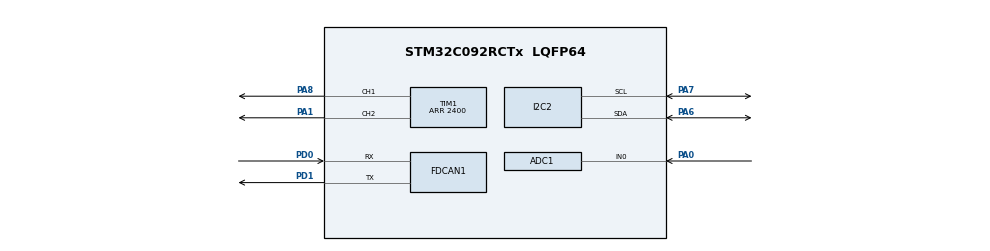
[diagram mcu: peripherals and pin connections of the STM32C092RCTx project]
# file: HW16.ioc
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ADC1.NbrOfConversionFlag=0
ADC1.SelectedChannel=ADC_CHANNEL_0
ADC1.master=1
FDCAN1.AutoRetransmission=ENABLE
FDCAN1.CalculateBaudRateData=1000000
FDCAN1.CalculateBaudRateNominal=1000000
FDCAN1.CalculateTimeBitNominal=1000
FDCAN1.CalculateTimeQuantumNominal=20.833333333333332
FDCAN1.DataSyncJumpWidth=6
FDCAN1.DataTimeSeg1=17
FDCAN1.DataTimeSeg2=6
FDCAN1.FrameFormat=FDCAN_FRAME_FD_BRS
FDCAN1.NominalPrescaler=1
FDCAN1.NominalSyncJumpWidth=12
FDCAN1.NominalTimeSeg1=35
FDCAN1.NominalTimeSeg2=12
FDCAN1.StdFiltersNbr=1
FDCAN1.TransmitPause=ENABLE
I2C2.Timing=0x10805D88
Mcu.Family=STM32C0
Mcu.Name=STM32C092RCTx
Mcu.Package=LQFP64
NUCLEO-C092RC.LD1=true
NUCLEO-C092RC.LD2=true
NUCLEO-C092RC.VCP=true
NVIC.TIM2_IRQn=true\:0\:0\:false\:false\:true\:true\:true\:true
PA0.Mode=IN0
PA0.Signal=ADC1_IN0
PA1.Signal=S_TIM1_CH2
PA6.Mode=I2C
PA6.Signal=I2C2_SDA
PA7.Mode=I2C
PA7.Signal=I2C2_SCL
PA8.Signal=S_TIM1_CH1
PD0.Mode=FDCAN_Activate
PD0.Signal=FDCAN1_RX
PD1.Mode=FDCAN_Activate
PD1.Signal=FDCAN1_TX
ProjectManager.HeapSize=0x200
ProjectManager.StackSize=0x400
ProjectManager.TargetToolchain=STM32CubeIDE
RCC.ADCFreq_Value=48000000
RCC.AHBFreq_Value=48000000
RCC.CortexFreq_Value=48000000
RCC.EXTERNAL_CLOCK_VALUE=12288000
RCC.HCLKFreq_Value=48000000
RCC.HSE_VALUE=8000000
RCC.HSISYSCLKDivider=RCC_HSI_DIV1
RCC.HSI_VALUE=48000000
RCC.LSE_VALUE=32768
RCC.SYSCLKFreq_VALUE=48000000
SH.S_TIM1_CH1.0=TIM1_CH1,PWM Generation1 CH1
SH.S_TIM1_CH2.0=TIM1_CH2,PWM Generation2 CH2
TIM1.Channel-PWM\ Generation1\ CH1=TIM_CHANNEL_1
TIM1.Channel-PWM\ Generation2\ CH2=TIM_CHANNEL_2
TIM1.Period=2400
TIM2.Period=48000
VP_NUCLEO-C092RC_VS_BSP_COMMON.Mode=COMMON
VP_TIM2_VS_ClockSourceINT.Mode=Internal
board=NUCLEO-C092RC

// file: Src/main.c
/* USER CODE BEGIN Header */
/**
  ******************************************************************************
  * @file           : main.c
  * @brief          : Main program body
  ******************************************************************************
  * @attention
  *
  * Copyright (c) 2026 STMicroelectronics.
  * All rights reserved.
  *
  * This software is licensed under terms that can be found in the LICENSE file
  * in the root directory of this software component.
  * If no LICENSE file comes with this software, it is provided AS-IS.
  *
  ******************************************************************************
  */
/* USER CODE END Header */
#include "main.h"

COM_InitTypeDef BspCOMInit;
ADC_HandleTypeDef hadc1;

FDCAN_HandleTypeDef hfdcan1;

I2C_HandleTypeDef hi2c2;

TIM_HandleTypeDef htim1;
TIM_HandleTypeDef htim2;

void SystemClock_Config(void);
static void MX_GPIO_Init(void);
static void MX_FDCAN1_Init(void);
static void MX_ADC1_Init(void);
static void MX_I2C2_Init(void);
static void MX_TIM1_Init(void);
static void MX_TIM2_Init(void);

uint32_t read_adc(void) {
    uint32_t raw;
    HAL_ADC_Start(&hadc1);
    if (HAL_ADC_PollForConversion(&hadc1, 10) == HAL_OK) {
        raw = HAL_ADC_GetValue(&hadc1);
    } else {
        raw = 0;
    }
    HAL_ADC_Stop(&hadc1);
    return raw;
}

#define INA219_ADDR 0x40
#define INA219_REG_CURRENT 0x04
#define INA219_REG_CALIB 0x05
#define INA219_REG_CONFIG 0x00

void writeINA219(int reg, int value) {
    uint8_t buf[3];
    buf[0] = reg;
    buf[1] = value >> 8;
    buf[2] = value & 0xff;
    HAL_I2C_Master_Transmit(&hi2c2, INA219_ADDR<<1, buf, 3, 10);
}

signed short readINA219(unsigned char reg) {
    HAL_I2C_Master_Transmit(&hi2c2, INA219_ADDR<<1, &reg, 1, 10);
    uint8_t buffer[2];
    HAL_I2C_Master_Receive(&hi2c2, INA219_ADDR<<1, buffer, 2, 10);
    return (signed short)((buffer[0]<<8)|buffer[1]);
}

void init_ina219(void) {
    writeINA219(INA219_REG_CALIB, 1024);
    writeINA219(INA219_REG_CONFIG, 0b0011000010001111);
}

// --- PI current control ---
volatile int state = 0;
volatile int counter = 0;
volatile float desired_current = 100.0;   // mA target, sign flips
volatile float integral = 0.0;

#define NSAMP 400
volatile int idx = 0;
float saved_desired[NSAMP];
float saved_actual[NSAMP];

float kp = 2.0;     // TUNE
float ki = 0.15;    // TUNE

void HAL_TIM_PeriodElapsedCallback(TIM_HandleTypeDef *htim) {
    if (htim == &htim2) {
        uint32_t pos = read_adc();

        // safety end-stops
        if (pos < 250 || pos > (4095 - 250)) {
            __HAL_TIM_SET_COMPARE(&htim1, TIM_CHANNEL_1, 2400);
            __HAL_TIM_SET_COMPARE(&htim1, TIM_CHANNEL_2, 2400);
            return;
        }

        if (state == 1) {
            float actual = readINA219(INA219_REG_CURRENT) / 3.0;  // mA
            float error = desired_current - actual;
            integral += error;

            float u = kp * error + ki * integral;
            if (u > 2400) u = 2400;
            if (u < -2400) u = -2400;

            if (u >= 0) {
                __HAL_TIM_SET_COMPARE(&htim1, TIM_CHANNEL_1, 2400);
                __HAL_TIM_SET_COMPARE(&htim1, TIM_CHANNEL_2, 2400 - (int)u);
            } else {
                __HAL_TIM_SET_COMPARE(&htim1, TIM_CHANNEL_2, 2400);
                __HAL_TIM_SET_COMPARE(&htim1, TIM_CHANNEL_1, 2400 - (int)(-u));
            }

            if (idx < NSAMP) {
                saved_desired[idx] = desired_current;
                saved_actual[idx] = actual;
                idx++;
            }

            counter++;
            if (counter >= 100) {
                desired_current = -desired_current;
                counter = 0;
            }
            if (idx >= NSAMP) {
                __HAL_TIM_SET_COMPARE(&htim1, TIM_CHANNEL_1, 2400);
                __HAL_TIM_SET_COMPARE(&htim1, TIM_CHANNEL_2, 2400);
                state = 0;
                counter = 0;
                integral = 0;
            }
        }
    }
}
/* USER CODE END 0 */

int main(void)
{

  /* MCU Configuration--------------------------------------------------------*/

  /* Reset of all peripherals, Initializes the Flash interface and the Systick. */
  HAL_Init();

  /* Configure the system clock */
  SystemClock_Config();

  /* Initialize all configured peripherals */
  MX_GPIO_Init();
  MX_FDCAN1_Init();
  MX_ADC1_Init();
  MX_I2C2_Init();
  MX_TIM1_Init();
  MX_TIM2_Init();
  /* USER CODE BEGIN 2 */
  init_ina219();
  HAL_TIM_Base_Start_IT(&htim2);
  init_ina219();
    HAL_TIM_Base_Start_IT(&htim2);
    __HAL_TIM_SET_COMPARE(&htim1, TIM_CHANNEL_1, 2400);   // 2400 = off
    __HAL_TIM_SET_COMPARE(&htim1, TIM_CHANNEL_2, 2400);   // 2400 = off
    HAL_TIM_PWM_Start(&htim1, TIM_CHANNEL_1);
    HAL_TIM_PWM_Start(&htim1, TIM_CHANNEL_2);
  /* USER CODE END 2 */

  /* Initialize leds */
  BSP_LED_Init(LED_GREEN);
  BSP_LED_Init(LED_BLUE);

  /* Initialize COM1 port (115200, 8 bits (7-bit data + 1 stop bit), no parity */
  BspCOMInit.BaudRate   = 115200;
  BspCOMInit.WordLength = COM_WORDLENGTH_8B;
  BspCOMInit.StopBits   = COM_STOPBITS_1;
  BspCOMInit.Parity     = COM_PARITY_NONE;
  BspCOMInit.HwFlowCtl  = COM_HWCONTROL_NONE;
  if (BSP_COM_Init(COM1, &BspCOMInit) != BSP_ERROR_NONE)
  {
    Error_Handler();
  }

  /* Infinite loop */
  while (1)
  {
	  uint8_t c;
	      if (HAL_UART_Receive(&hcom_uart[COM1], &c, 1, 10) == HAL_OK) {
	          if (c == 'a') {
	              idx = 0;
	              integral = 0;
	              counter = 0;
	              state = 1;
	              while (state == 1) {}

	              // primt data
	              for (int i = 0; i < NSAMP; i++) {
	                  printf("%d,%d,%d\r\n", i, (int)saved_desired[i], (int)saved_actual[i]);
	              }
	          }
	      }
  }
}

void SystemClock_Config(void)
{
  RCC_OscInitTypeDef RCC_OscInitStruct = {0};
  RCC_ClkInitTypeDef RCC_ClkInitStruct = {0};

  __HAL_FLASH_SET_LATENCY(FLASH_LATENCY_1);

  /** Initializes the RCC Oscillators according to the specified parameters
  * in the RCC_OscInitTypeDef structure.
  */
  RCC_OscInitStruct.OscillatorType = RCC_OSCILLATORTYPE_HSI;
  RCC_OscInitStruct.HSIState = RCC_HSI_ON;
  RCC_OscInitStruct.HSIDiv = RCC_HSI_DIV1;
  RCC_OscInitStruct.HSICalibrationValue = RCC_HSICALIBRATION_DEFAULT;
  if (HAL_RCC_OscConfig(&RCC_OscInitStruct) != HAL_OK)
  {
    Error_Handler();
  }

  /** Initializes the CPU, AHB and APB buses clocks
  */
  RCC_ClkInitStruct.ClockType = RCC_CLOCKTYPE_HCLK|RCC_CLOCKTYPE_SYSCLK
                              |RCC_CLOCKTYPE_PCLK1;
  RCC_ClkInitStruct.SYSCLKSource = RCC_SYSCLKSOURCE_HSI;
  RCC_ClkInitStruct.SYSCLKDivider = RCC_SYSCLK_DIV1;
  RCC_ClkInitStruct.AHBCLKDivider = RCC_HCLK_DIV1;
  RCC_ClkInitStruct.APB1CLKDivider = RCC_APB1_DIV1;

  if (HAL_RCC_ClockConfig(&RCC_ClkInitStruct, FLASH_LATENCY_1) != HAL_OK)
  {
    Error_Handler();
  }
}

static void MX_ADC1_Init(void)
{

  ADC_ChannelConfTypeDef sConfig = {0};

  /** Configure the global features of the ADC (Clock, Resolution, Data Alignment and number of conversion)
  */
  hadc1.Instance = ADC1;
  hadc1.Init.ClockPrescaler = ADC_CLOCK_SYNC_PCLK_DIV2;
  hadc1.Init.Resolution = ADC_RESOLUTION_12B;
  hadc1.Init.DataAlign = ADC_DATAALIGN_RIGHT;
  hadc1.Init.ScanConvMode = ADC_SCAN_SEQ_FIXED;
  hadc1.Init.EOCSelection = ADC_EOC_SINGLE_CONV;
  hadc1.Init.LowPowerAutoWait = DISABLE;
  hadc1.Init.LowPowerAutoPowerOff = DISABLE;
  hadc1.Init.ContinuousConvMode = DISABLE;
  hadc1.Init.NbrOfConversion = 1;
  hadc1.Init.DiscontinuousConvMode = DISABLE;
  hadc1.Init.ExternalTrigConv = ADC_SOFTWARE_START;
  hadc1.Init.ExternalTrigConvEdge = ADC_EXTERNALTRIGCONVEDGE_NONE;
  hadc1.Init.DMAContinuousRequests = DISABLE;
  hadc1.Init.Overrun = ADC_OVR_DATA_PRESERVED;
  hadc1.Init.SamplingTimeCommon1 = ADC_SAMPLETIME_1CYCLE_5;
  hadc1.Init.OversamplingMode = DISABLE;
  hadc1.Init.TriggerFrequencyMode = ADC_TRIGGER_FREQ_HIGH;
  if (HAL_ADC_Init(&hadc1) != HAL_OK)
  {
    Error_Handler();
  }

  /** Configure Regular Channel
  */
  sConfig.Channel = ADC_CHANNEL_0;
  sConfig.Rank = ADC_RANK_CHANNEL_NUMBER;
  if (HAL_ADC_ConfigChannel(&hadc1, &sConfig) != HAL_OK)
  {
    Error_Handler();
  }

}

static void MX_FDCAN1_Init(void)
{

  hfdcan1.Instance = FDCAN1;
  hfdcan1.Init.ClockDivider = FDCAN_CLOCK_DIV1;
  hfdcan1.Init.FrameFormat = FDCAN_FRAME_FD_BRS;
  hfdcan1.Init.Mode = FDCAN_MODE_NORMAL;
  hfdcan1.Init.AutoRetransmission = ENABLE;
  hfdcan1.Init.TransmitPause = ENABLE;
  hfdcan1.Init.ProtocolException = DISABLE;
  hfdcan1.Init.NominalPrescaler = 1;
  hfdcan1.Init.NominalSyncJumpWidth = 12;
  hfdcan1.Init.NominalTimeSeg1 = 35;
  hfdcan1.Init.NominalTimeSeg2 = 12;
  hfdcan1.Init.DataPrescaler = 1;
  hfdcan1.Init.DataSyncJumpWidth = 6;
  hfdcan1.Init.DataTimeSeg1 = 17;
  hfdcan1.Init.DataTimeSeg2 = 6;
  hfdcan1.Init.StdFiltersNbr = 1;
  hfdcan1.Init.ExtFiltersNbr = 0;
  hfdcan1.Init.TxFifoQueueMode = FDCAN_TX_FIFO_OPERATION;
  if (HAL_FDCAN_Init(&hfdcan1) != HAL_OK)
  {
    Error_Handler();
  }

}

static void MX_I2C2_Init(void)
{

  hi2c2.Instance = I2C2;
  hi2c2.Init.Timing = 0x10805D88;
  hi2c2.Init.OwnAddress1 = 0;
  hi2c2.Init.AddressingMode = I2C_ADDRESSINGMODE_7BIT;
  hi2c2.Init.DualAddressMode = I2C_DUALADDRESS_DISABLE;
  hi2c2.Init.OwnAddress2 = 0;
  hi2c2.Init.OwnAddress2Masks = I2C_OA2_NOMASK;
  hi2c2.Init.GeneralCallMode = I2C_GENERALCALL_DISABLE;
  hi2c2.Init.NoStretchMode = I2C_NOSTRETCH_DISABLE;
  if (HAL_I2C_Init(&hi2c2) != HAL_OK)
  {
    Error_Handler();
  }

  /** Configure Analogue filter
  */
  if (HAL_I2CEx_ConfigAnalogFilter(&hi2c2, I2C_ANALOGFILTER_ENABLE) != HAL_OK)
  {
    Error_Handler();
  }

  /** Configure Digital filter
  */
  if (HAL_I2CEx_ConfigDigitalFilter(&hi2c2, 0) != HAL_OK)
  {
    Error_Handler();
  }

}

static void MX_TIM1_Init(void)
{

  TIM_MasterConfigTypeDef sMasterConfig = {0};
  TIM_OC_InitTypeDef sConfigOC = {0};
  TIM_BreakDeadTimeConfigTypeDef sBreakDeadTimeConfig = {0};

  htim1.Instance = TIM1;
  htim1.Init.Prescaler = 0;
  htim1.Init.CounterMode = TIM_COUNTERMODE_UP;
  htim1.Init.Period = 2400;
  htim1.Init.ClockDivision = TIM_CLOCKDIVISION_DIV1;
  htim1.Init.RepetitionCounter = 0;
  htim1.Init.AutoReloadPreload = TIM_AUTORELOAD_PRELOAD_DISABLE;
  if (HAL_TIM_PWM_Init(&htim1) != HAL_OK)
  {
    Error_Handler();
  }
  sMasterConfig.MasterOutputTrigger = TIM_TRGO_RESET;
  sMasterConfig.MasterOutputTrigger2 = TIM_TRGO2_RESET;
  sMasterConfig.MasterSlaveMode = TIM_MASTERSLAVEMODE_DISABLE;
  if (HAL_TIMEx_MasterConfigSynchronization(&htim1, &sMasterConfig) != HAL_OK)
  {
    Error_Handler();
  }
  sConfigOC.OCMode = TIM_OCMODE_PWM1;
  sConfigOC.Pulse = 0;
  sConfigOC.OCPolarity = TIM_OCPOLARITY_HIGH;
  sConfigOC.OCNPolarity = TIM_OCNPOLARITY_HIGH;
  sConfigOC.OCFastMode = TIM_OCFAST_DISABLE;
  sConfigOC.OCIdleState = TIM_OCIDLESTATE_RESET;
  sConfigOC.OCNIdleState = TIM_OCNIDLESTATE_RESET;
  if (HAL_TIM_PWM_ConfigChannel(&htim1, &sConfigOC, TIM_CHANNEL_1) != HAL_OK)
  {
    Error_Handler();
  }
  if (HAL_TIM_PWM_ConfigChannel(&htim1, &sConfigOC, TIM_CHANNEL_2) != HAL_OK)
  {
    Error_Handler();
  }
  sBreakDeadTimeConfig.OffStateRunMode = TIM_OSSR_DISABLE;
  sBreakDeadTimeConfig.OffStateIDLEMode = TIM_OSSI_DISABLE;
  sBreakDeadTimeConfig.LockLevel = TIM_LOCKLEVEL_OFF;
  sBreakDeadTimeConfig.DeadTime = 0;
  sBreakDeadTimeConfig.BreakState = TIM_BREAK_DISABLE;
  sBreakDeadTimeConfig.BreakPolarity = TIM_BREAKPOLARITY_HIGH;
  sBreakDeadTimeConfig.BreakFilter = 0;
  sBreakDeadTimeConfig.BreakAFMode = TIM_BREAK_AFMODE_INPUT;
  sBreakDeadTimeConfig.Break2State = TIM_BREAK2_DISABLE;
  sBreakDeadTimeConfig.Break2Polarity = TIM_BREAK2POLARITY_HIGH;
  sBreakDeadTimeConfig.Break2Filter = 0;
  sBreakDeadTimeConfig.Break2AFMode = TIM_BREAK_AFMODE_INPUT;
  sBreakDeadTimeConfig.AutomaticOutput = TIM_AUTOMATICOUTPUT_DISABLE;
  if (HAL_TIMEx_ConfigBreakDeadTime(&htim1, &sBreakDeadTimeConfig) != HAL_OK)
  {
    Error_Handler();
  }
  HAL_TIM_MspPostInit(&htim1);

}

static void MX_TIM2_Init(void)
{

  TIM_ClockConfigTypeDef sClockSourceConfig = {0};
  TIM_MasterConfigTypeDef sMasterConfig = {0};

  htim2.Instance = TIM2;
  htim2.Init.Prescaler = 0;
  htim2.Init.CounterMode = TIM_COUNTERMODE_UP;
  htim2.Init.Period = 48000;
  htim2.Init.ClockDivision = TIM_CLOCKDIVISION_DIV1;
  htim2.Init.AutoReloadPreload = TIM_AUTORELOAD_PRELOAD_DISABLE;
  if (HAL_TIM_Base_Init(&htim2) != HAL_OK)
  {
    Error_Handler();
  }
  sClockSourceConfig.ClockSource = TIM_CLOCKSOURCE_INTERNAL;
  if (HAL_TIM_ConfigClockSource(&htim2, &sClockSourceConfig) != HAL_OK)
  {
    Error_Handler();
  }
  sMasterConfig.MasterOutputTrigger = TIM_TRGO_RESET;
  sMasterConfig.MasterSlaveMode = TIM_MASTERSLAVEMODE_DISABLE;
  if (HAL_TIMEx_MasterConfigSynchronization(&htim2, &sMasterConfig) != HAL_OK)
  {
    Error_Handler();
  }

}

static void MX_GPIO_Init(void)
{

  /* GPIO Ports Clock Enable */
  __HAL_RCC_GPIOA_CLK_ENABLE();
  __HAL_RCC_GPIOD_CLK_ENABLE();

}

void Error_Handler(void)
{
  __disable_irq();
  while (1)
  {
  }
}
